# nrf52833 register map
Vendor: Nordic Semiconductor; Series: nrf52; File version: 1
CPU: CM4 r0p1, little endian, MPU, FPU, 3 interrupt priority bits
Registers are 32-bit, read-write, reset 0x0 unless marked. A register's access mark holds for its fields unless they carry their own. Offsets are from the block's base; [hi:lo] are bit positions; {n}, {i} and the like mark numbered series.

## UICR — User information configuration registers
Base 0x10001000
{0x14+4i} NRFFW[{i}] (i=0..12) reset 0xFFFFFFFF — Description collection: Reserved for Nordic firmware design
  [31:0] NRFFW — Reserved for Nordic firmware design
{0x50+4i} NRFHW[{i}] (i=0..11) reset 0xFFFFFFFF — Description collection: Reserved for Nordic hardware design
  [31:0] NRFHW — Reserved for Nordic hardware design
{0x80+4i} CUSTOMER[{i}] (i=0..31) reset 0xFFFFFFFF — Description collection: Reserved for customer
  [31:0] CUSTOMER — Reserved for customer
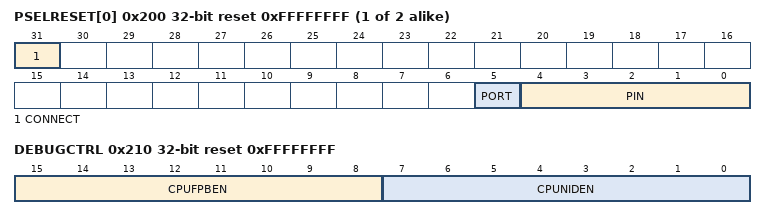
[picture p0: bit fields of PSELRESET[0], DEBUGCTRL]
{0x200+4i} PSELRESET[{i}] (i=0..1) reset 0xFFFFFFFF — Description collection: Mapping of the nRESET function (see POWER chapter for details)
  [31] CONNECT — Connection
    1=Disconnected; 0=Connected
  [5] PORT — Port number onto which nRESET is exposed
  [4:0] PIN — GPIO pin number onto which nRESET is exposed
0x208 APPROTECT reset 0xFFFFFFFF — Access port protection
  [7:0] PALL — Enable or disable access port protection.
    255=Disabled (Hardware disable of access port protection for devices where access port protection is controlled by hardware); 90=HwDisabled (Hardware disable of access port protection for devices where access port protection is controlled by hardware and software); 0=Enabled
0x20C NFCPINS reset 0xFFFFFFFF — Setting of pins dedicated to NFC functionality: NFC antenna or GPIO
  [0] PROTECT — Setting of pins dedicated to NFC functionality
    0=Disabled (Operation as GPIO pins. Same protection as normal GPIO pins.); 1=NFC (Operation as NFC antenna pins. Configures the protection for NFC operation.)
0x210 DEBUGCTRL reset 0xFFFFFFFF — Processor debug control
  [15:8] CPUFPBEN — Configure CPU flash patch and breakpoint (FPB) unit behavior
    255=Enabled (Enable CPU FPB unit (default behavior)); 0=Disabled (Disable CPU FPB unit. Writes into the FPB registers will be ignored.)
  [7:0] CPUNIDEN — Configure CPU non-intrusive debug features
    255=Enabled (Enable CPU ITM and ETM functionality (default behavior)); 0=Disabled (Disable CPU ITM and ETM functionality)
0x304 REGOUT0 reset 0xFFFFFFFF — Output voltage from REG0 regulator stage. The maximum output voltage from this stage is given as VDDH - V_VDDH-VDD.
  [2:0] VOUT — Output voltage from REG0 regulator stage.
    0=1V8 (1.8 V); 1=2V1 (2.1 V); 2=2V4 (2.4 V); 3=2V7 (2.7 V); 4=3V0 (3.0 V); 5=3V3 (3.3 V); 7=DEFAULT (Default voltage: 1.8 V)

## APPROTECT — Access Port Protection
Base 0x40000000
0x550 FORCEPROTECT rw-once reset 0xFFFFFFFF — Software force enable APPROTECT mechanism until next reset.
  [7:0] FORCEPROTECT — Write 0x0 to force enable APPROTECT mechanism
    on write: 0=Force (Software force enable APPROTECT mechanism)
0x558 DISABLE — Software disable APPROTECT mechanism
  [7:0] DISABLE
    90=SwDisable (Software disable APPROTECT mechanism)

## P0 — GPIO Port 1
Base 0x50000000
Same registers: P1 0x50000300 (alternate view of P0)
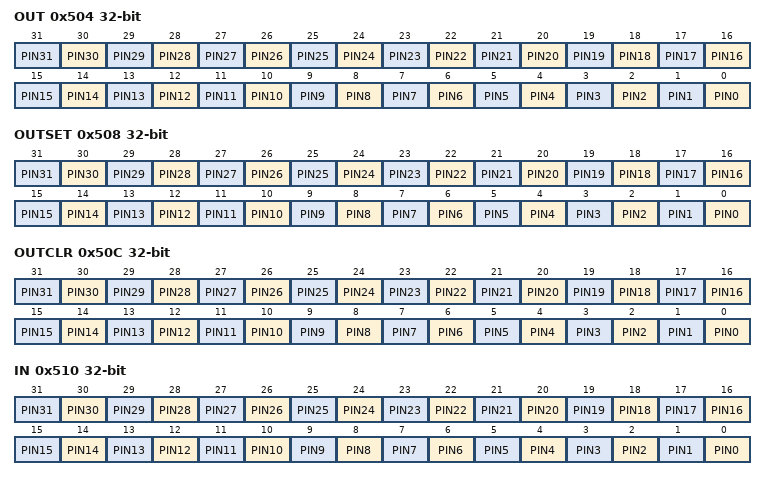
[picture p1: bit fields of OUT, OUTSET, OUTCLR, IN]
0x504 OUT — Write GPIO port
  [all] fields
    0=Low (Pin driver is low); 1=High (Pin driver is high)
  [n] PIN{n} (n=0..31)
0x508 OUTSET write-1-sets — Set individual bits in GPIO port
  [all] fields
    on read: 0=Low (Read: pin driver is low); 1=High (Read: pin driver is high) | on write: 1=Set (Write: a '1' sets the pin high; a '0' has no effect)
  [n] PIN{n} (n=0..31)
0x50C OUTCLR write-1-clears — Clear individual bits in GPIO port
  [all] fields
    on read: 0=Low (Read: pin driver is low); 1=High (Read: pin driver is high) | on write: 1=Clear (Write: a '1' sets the pin low; a '0' has no effect)
  [n] PIN{n} (n=0..31)
0x510 IN ro — Read GPIO port
  [all] fields
    0=Low (Pin input is low); 1=High (Pin input is high)
  [n] PIN{n} (n=0..31)
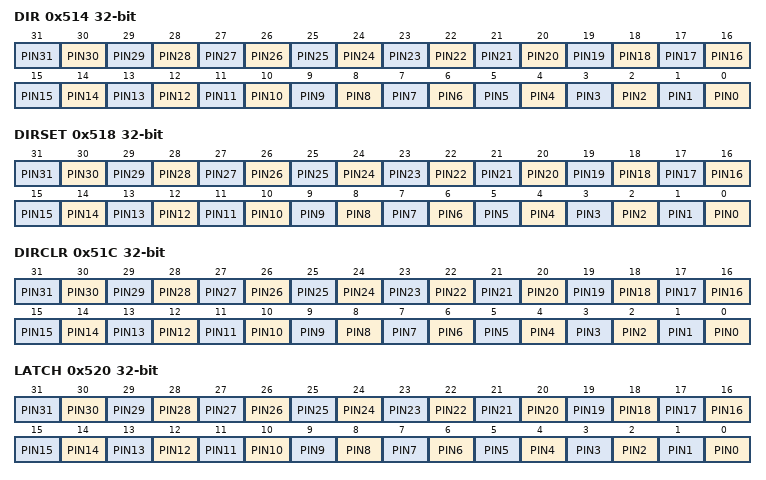
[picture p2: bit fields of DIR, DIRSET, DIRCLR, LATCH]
0x514 DIR — Direction of GPIO pins
  [all] fields
    0=Input (Pin set as input); 1=Output (Pin set as output)
  [n] PIN{n} (n=0..31)
0x518 DIRSET write-1-sets
  [all] fields
    on read: 0=Input (Read: pin set as input); 1=Output (Read: pin set as output) | on write: 1=Set (Write: a '1' sets pin to output; a '0' has no effect)
  [n] PIN{n} (n=0..31) — Set as output pin {n}
0x51C DIRCLR write-1-clears — DIR clear register
  [all] fields
    on read: 0=Input (Read: pin set as input); 1=Output (Read: pin set as output) | on write: 1=Clear (Write: a '1' sets pin to input; a '0' has no effect)
  [n] PIN{n} (n=0..31) — Set as input pin {n}
0x520 LATCH — Latch register indicating what GPIO pins that have met the criteria set in the PIN_CNF[n].SENSE registers
  [all] fields
    0=NotLatched (Criteria has not been met); 1=Latched (Criteria has been met)
  [n] PIN{n} (n=0..31) — Status on whether PIN{n} has met criteria set in PIN_CNF{n}.SENSE register. Write '1' to clear.
0x524 DETECTMODE — Select between default DETECT signal behavior and LDETECT mode
  [0] DETECTMODE
    0=Default (DETECT directly connected to PIN DETECT signals); 1=LDETECT (Use the latched LDETECT behavior)
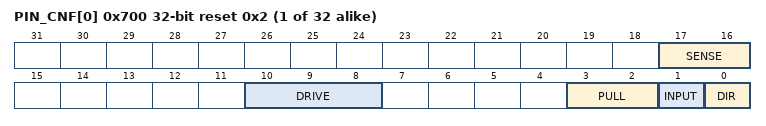
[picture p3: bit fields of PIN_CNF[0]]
{0x700+4i} PIN_CNF[{i}] (i=0..31) reset 0x2 — Description collection: Configuration of GPIO pins
  [17:16] SENSE — Pin sensing mechanism
    0=Disabled; 2=High (Sense for high level); 3=Low (Sense for low level)
  [10:8] DRIVE — Drive configuration
    0=S0S1 (Standard '0', standard '1'); 1=H0S1 (High drive '0', standard '1'); 2=S0H1 (Standard '0', high drive '1'); 3=H0H1 (High drive '0', high 'drive '1''); 4=D0S1 (Disconnect '0' standard '1' (normally used for wired-or connections)); 5=D0H1 (Disconnect '0', high drive '1' (normally used for wired-or connections)); 6=S0D1 (Standard '0'. disconnect '1' (normally used for wired-and connections)); 7=H0D1 (High drive '0', disconnect '1' (normally used for wired-and connections))
  [3:2] PULL — Pull configuration
    0=Disabled (No pull); 1=Pull down on pin; 3=Pull up on pin
  [1] INPUT — Connect or disconnect input buffer
    0=Connect input buffer; 1=Disconnect input buffer
  [0] DIR — Pin direction. Same physical register as DIR register
    0=Input (Configure pin as an input pin); 1=Output (Configure pin as an output pin)

## Notices in the file
Copyright (c) 2010 - 2024, Nordic Semiconductor ASA
All rights reserved.
Redistribution and use in source and binary forms, with or without modification,
are permitted provided that the following conditions are met:
1. Redistributions of source code must retain the above copyright notice, this
list of conditions and the following disclaimer.
2. Redistributions in binary form, except as embedded into a Nordic
Semiconductor ASA integrated circuit in a product or a software update for
such product, must reproduce the above copyright notice, this list of
conditions and the following disclaimer in the documentation and/or other
materials provided with the distribution.
3. Neither the name of Nordic Semiconductor ASA nor the names of its
contributors may be used to endorse or promote products derived from this
software without specific prior written permission.
4. This software, with or without modification, must only be used with a
Nordic Semiconductor ASA integrated circuit.
5. Any software provided in binary form under this license must not be reverse
engineered, decompiled, modified and/or disassembled.
THIS SOFTWARE IS PROVIDED BY NORDIC SEMICONDUCTOR ASA "AS IS" AND ANY EXPRESS
OR IMPLIED WARRANTIES, INCLUDING, BUT NOT LIMITED TO, THE IMPLIED WARRANTIES
OF MERCHANTABILITY, NONINFRINGEMENT, AND FITNESS FOR A PARTICULAR PURPOSE ARE
DISCLAIMED. IN NO EVENT SHALL NORDIC SEMICONDUCTOR ASA OR CONTRIBUTORS BE
LIABLE FOR ANY DIRECT, INDIRECT, INCIDENTAL, SPECIAL, EXEMPLARY, OR
CONSEQUENTIAL DAMAGES (INCLUDING, BUT NOT LIMITED TO, PROCUREMENT OF SUBSTITUTE
GOODS OR SERVICES; LOSS OF USE, DATA, OR PROFITS; OR BUSINESS INTERRUPTION)
HOWEVER CAUSED AND ON ANY THEORY OF LIABILITY, WHETHER IN CONTRACT, STRICT
LIABILITY, OR TORT (INCLUDING NEGLIGENCE OR OTHERWISE) ARISING IN ANY WAY OUT
OF THE USE OF THIS SOFTWARE, EVEN IF ADVISED OF THE POSSIBILITY OF SUCH DAMAGE.
